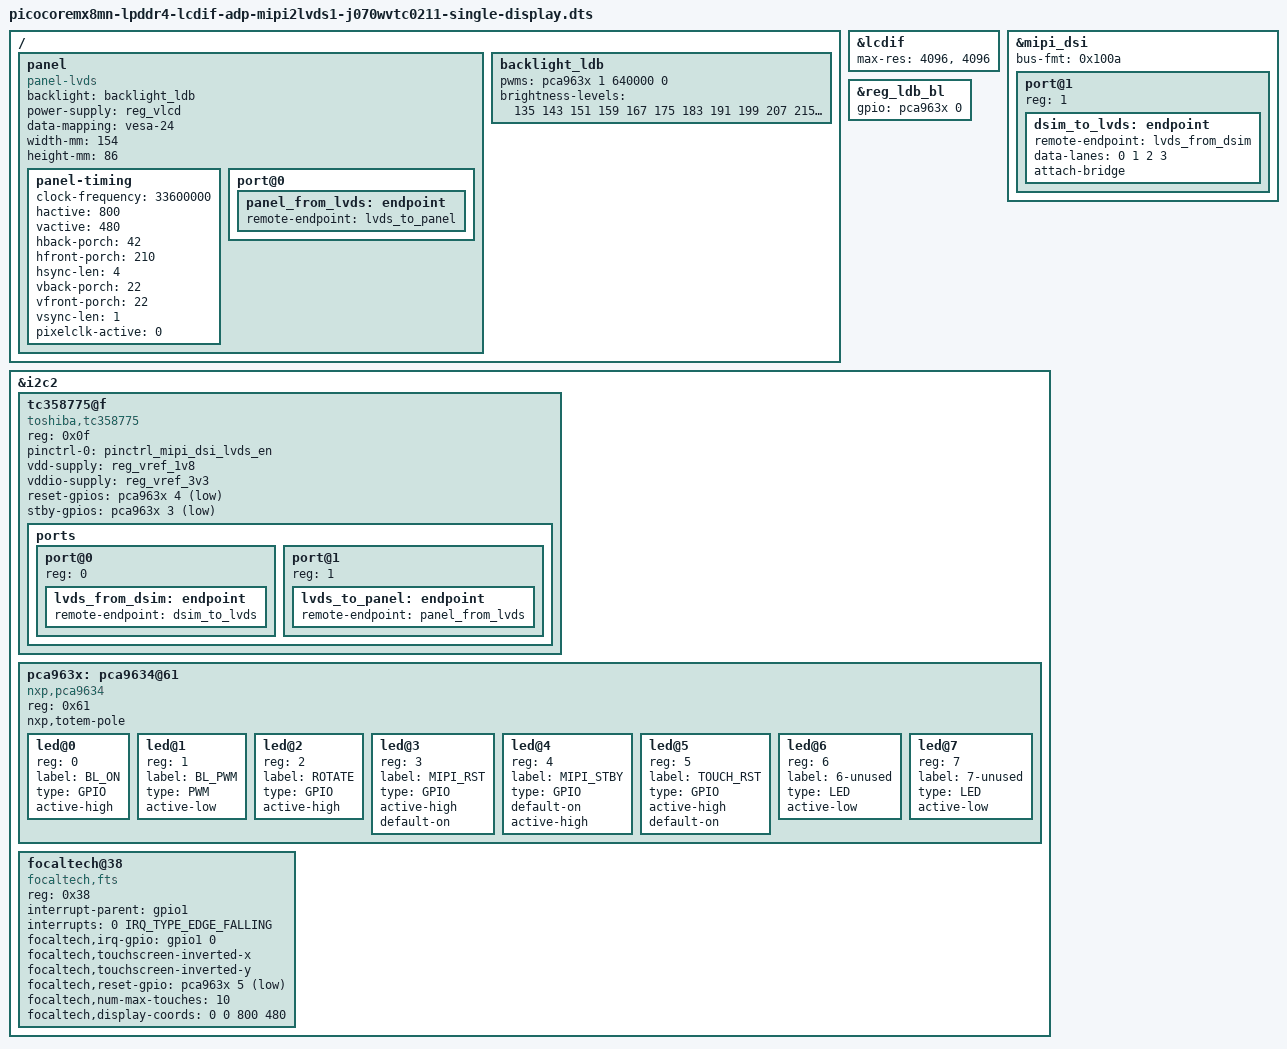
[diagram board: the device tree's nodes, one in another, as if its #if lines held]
/*
 * Copyright (C) 2021 F&S Elektronik Systeme GmbH
 *
 * This program is free software; you can redistribute it and/or modify
 * it under the terms of the GNU General Public License version 2 as
 * published by the Free Software Foundation.
 */

#define CONFIG_PICOCOREMX8MN_MIPI_DSI_LVDS
#define CONFIG_PICOCOREMX8MN_INVERTED_XY
#include "picocoremx8mn-lpddr4.dts"

&lcdif {
	status = "okay";
	/* important to overwrite max-res otherwise DRM lcdif will fail
	 * to find a suitable connector
	 */
	max-res = <4096>, <4096>;
};


&mipi_dsi {
	status = "okay";

	bus-fmt = <0x100a>;

	port@1 {
		reg = <1>;
		dsim_to_lvds: endpoint {
			remote-endpoint = <&lvds_from_dsim>;
			data-lanes = <0 1 2 3>;
			attach-bridge;
		};
	};
};

/{
	panel: panel {
		compatible = "panel-lvds";
		backlight = <&backlight_ldb>;
		power-supply = <&reg_vlcd>;

		data-mapping = "vesa-24";
		width-mm = <154>;
		height-mm = <86>;

		panel-timing {
				clock-frequency = <33600000>;
				hactive = <800>;
				vactive = <480>;
				hback-porch = <42>;
				hfront-porch = <210>;
				hsync-len = <4>;
				vback-porch = <22>;
				vfront-porch = <22>;
				vsync-len = <1>;
				pixelclk-active = <0>;
		};

		port@0 {
			panel_from_lvds: endpoint {
				remote-endpoint = <&lvds_to_panel>;
			};
		};
	};

	backlight_ldb: backlight_ldb {
		pwms = <&pca963x 1 640000 0>;
		brightness-levels = <135 143 151 159 167 175 183 191
				     199 207 215 223 231 239 247 255>;
	};
};

&reg_ldb_bl {
	gpio = <&pca963x 0 GPIO_ACTIVE_HIGH>;
};

&i2c2 {
	tc358775@f {

		compatible = "toshiba,tc358775";
		reg = <0x0f>;
		pinctrl-names = "default";
		pinctrl-0 = <&pinctrl_mipi_dsi_lvds_en>;
		vdd-supply = <&reg_vref_1v8>;
		vddio-supply = <&reg_vref_3v3>;
		reset-gpios = <&pca963x 4 GPIO_ACTIVE_LOW>;
		stby-gpios  = <&pca963x 3 GPIO_ACTIVE_LOW>;
		ports {
			#address-cells = <1>;
			#size-cells = <0>;

			port@0 {
				reg = <0>;

				lvds_from_dsim: endpoint {
					remote-endpoint = <&dsim_to_lvds>;
				};
			};

			port@1 {
				reg = <1>;

				lvds_to_panel: endpoint {
					remote-endpoint = <&panel_from_lvds>;
				};
			};
		};
	};

	pca963x: pca9634@61 {
			compatible = "nxp,pca9634";
			reg = <0x61>;
			nxp,totem-pole;
			#address-cells = <1>;
			#size-cells = <0>;
			#pwm-cells = <3>;
			#gpio-cells = <2>;
			led@0 {
				reg = <0>;
				label = "BL_ON";
				type = "GPIO";
				active-high;
			};
			led@1 {
				reg = <1>;
				label = "BL_PWM";
				type = "PWM";
				active-low;
			};
			led@2 {
				reg = <2>;
				label = "ROTATE";
				type = "GPIO";
				active-high;
			};
			led@3 {
				reg = <3>;
				label = "MIPI_RST";
				type = "GPIO";
				active-high;
				default-on;		/* or: keep-value */
			};
			led@4 {
				reg = <4>;
				label = "MIPI_STBY";
				type = "GPIO";
				default-on;		/* or: keep-value */
				active-high;
			};
			led@5 {
				reg = <5>;
				label = "TOUCH_RST";
				type = "GPIO";
				active-high;
				default-on;		/* or: keep-value */
			};
			led@6 {
				reg = <6>;
				label = "6-unused";
				type = "LED";
				active-low;
			};
			led@7 {
				reg = <7>;
				label = "7-unused";
				type = "LED";
				active-low;
			};
		};

	/* touch I2C */
	focaltech@38 {
		compatible = "focaltech,fts";
		reg = <0x38>;
#if CONFIG_PICOCOREMX8MN_BOARD_REVISION >= 130
		interrupt-parent = <&gpio1>;
		interrupts = <0 IRQ_TYPE_EDGE_FALLING>;
		focaltech,irq-gpio = <&gpio1 0 IRQ_TYPE_EDGE_FALLING>;
#else
		interrupt-parent = <&gpio4>;
		interrupts = <31 IRQ_TYPE_EDGE_FALLING>;
		focaltech,irq-gpio = <&gpio4 31 IRQ_TYPE_EDGE_FALLING>;
#endif
#ifdef CONFIG_PICOCOREMX8MN_INVERTED_XY
		focaltech,touchscreen-inverted-x;
		focaltech,touchscreen-inverted-y;
#endif
#if CONFIG_PICOCOREBBDSI_BOARD_REVISION > 120
		focaltech,reset-gpio = <&pca963x 5 GPIO_ACTIVE_LOW>;
#endif
		focaltech,num-max-touches = <10>;
		focaltech,display-coords = <0 0 800 480>;
	};
};
